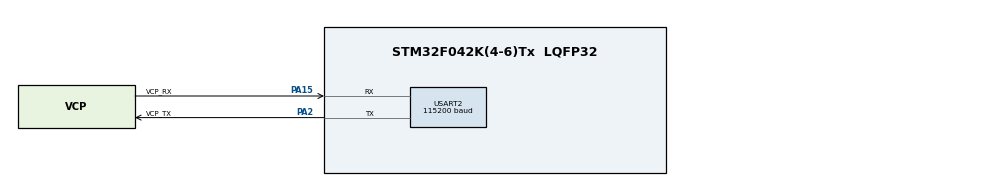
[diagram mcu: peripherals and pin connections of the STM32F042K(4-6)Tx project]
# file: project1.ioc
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Mcu.Family=STM32F0
Mcu.Name=STM32F042K(4-6)Tx
Mcu.Package=LQFP32
NVIC.USART2_IRQn=true\:0\:0\:false\:false\:true\:true\:true
PA13.GPIO_Label=SWDIO
PA13.Mode=Serial_Wire
PA13.Signal=SYS_SWDIO
PA14.GPIO_Label=SWCLK
PA14.Mode=Serial_Wire
PA14.Signal=SYS_SWCLK
PA15.GPIO_Label=VCP_RX
PA15.Mode=Asynchronous
PA15.Signal=USART2_RX
PA2.GPIO_Label=VCP_TX
PA2.Mode=Asynchronous
PA2.Signal=USART2_TX
PF0-OSC_IN.GPIO_Label=MCO
PF0-OSC_IN.Mode=HSE-External-Clock-Source
PF0-OSC_IN.Signal=RCC_OSC_IN
ProjectManager.HeapSize=0x200
ProjectManager.StackSize=0x400
ProjectManager.TargetToolchain=STM32CubeIDE
USART2.BaudRate=115200
USART2.VirtualMode-Asynchronous=VM_ASYNC
board=NUCLEO-F042K6

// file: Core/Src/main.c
/* USER CODE BEGIN Header */
/**
  ******************************************************************************
  * @file           : main.c
  * @brief          : Main program body
  ******************************************************************************
  * @attention
  *
  * Copyright (c) 2022 STMicroelectronics.
  * All rights reserved.
  *
  * This software is licensed under terms that can be found in the LICENSE file
  * in the root directory of this software component.
  * If no LICENSE file comes with this software, it is provided AS-IS.
  *
  ******************************************************************************
  */
/* USER CODE END Header */
#include "main.h"
#include "usart.h"
#include "gpio.h"
#include "jsmn.h"

/* USER CODE BEGIN PTD */
typedef unsigned char bool;

/* USER CODE END PTD */

/* USER CODE BEGIN PD */
#ifdef __GNUC__
  #define PUTCHAR_PROTOTYPE int __io_putchar(int ch)
#else
  #define PUTCHAR_PROTOTYPE int fputc(int ch, FILE *f)
#endif /* __GNUC__ */
#define BUFFER_SIZE 256
/* USER CODE END PD */

void SystemClock_Config(void);
/* USER CODE BEGIN PFP */
PUTCHAR_PROTOTYPE
{
	HAL_UART_Transmit(&huart2, (uint8_t *)&ch, 1, 0xFFFF);
	return ch;
}
/* USER CODE END PFP */

/* USER CODE BEGIN 0 */
uint8_t debug_rxBuf[BUFFER_SIZE];
uint8_t debug_rxData[BUFFER_SIZE];
uint8_t debug_aRxBuf;
uint8_t debug_rx_cnt = 0;
bool debug_rx_flag = false;
/* USER CODE END 0 */

int main(void)
{

  /* MCU Configuration--------------------------------------------------------*/

  /* Reset of all peripherals, Initializes the Flash interface and the Systick. */
  HAL_Init();

  /* Configure the system clock */
  SystemClock_Config();

  /* Initialize all configured peripherals */
  MX_GPIO_Init();
  MX_USART2_UART_Init();
  /* USER CODE BEGIN 2 */
  HAL_UART_Receive_IT(&huart2, &debug_aRxBuf, 1);

  /* USER CODE END 2 */

  /* Infinite loop */
  /* USER CODE BEGIN WHILE */
  printf("start\n");
  static const char *JSON_STRING =
      "{\"user\": \"johndoe\", \"admin\": false, \"uid\": 1000,\n  "
      "\"groups\": [\"users\", \"wheel\", \"audio\", \"video\"]}";
  jsmn_parser p;
  jsmntok_t t[128];
  jsmn_init(&p);
  int r = jsmn_parse(&p, JSON_STRING, strlen(JSON_STRING), t, sizeof(t)/sizeof(t[0]));
  for (int i = 1; i < r; i++)
  {
      if (jsoneq(JSON_STRING, &t[i], "user") == 0)
      {
          /* We may use strndup() to fetch string value */
          printf("- User: %.*s\n", t[i+1].end-t[i+1].start, JSON_STRING + t[i+1].start);
          i++;
      }
      else if (jsoneq(JSON_STRING, &t[i], "admin") == 0)
      {
           /* We may additionally check if the value is either "true" or "false" */
          printf("- Admin: %.*s\n", t[i+1].end-t[i+1].start, JSON_STRING + t[i+1].start);
          i++;
      }
  }
//  char text[]="{\"mode\":\"nest\",\"move\":0.7,\"turn\":-0.123,\"rc_servo\":{\"0\":125,\"3\":75,\"1\":0,\"11\":75},\"adc\":\"\",\"rc_request\":\"\"}";
//  cJSON *json,*result;
//  json = cJSON_Parse(text);
//  printf("json type = %d\n",json->type);
//  result  = cJSON_GetObjectItem(json,"mode");
//  printf("result type = %d\n",result->type);
//  printf("%s\n",result->valuestring);
//  result = cJSON_GetObjectItem(json,"rc_servo");
//  result = cJSON_GetObjectItem(result,"0");
//  printf("%d\n",result->valueint);
//  cJSON_Delete(json);
//  cJSON_Delete(result);

  while(1);
  while (1)
  {
	if (debug_rx_flag == true) {
		debug_rx_flag = false;
		char *msg = (char*)debug_rxData;
//		printf("recv: %s", msg);
		if (strcmp(msg, "adc")) {
			int adc = 87;
			printf("%d\n", adc);
		} else if (strcmp(msg, "adc")) {
			int adc = 87;
			printf("%d\n", adc);
		}
	}
    /* USER CODE END WHILE */

  }
}

void SystemClock_Config(void)
{
  RCC_OscInitTypeDef RCC_OscInitStruct = {0};
  RCC_ClkInitTypeDef RCC_ClkInitStruct = {0};

  /** Initializes the RCC Oscillators according to the specified parameters
  * in the RCC_OscInitTypeDef structure.
  */
  RCC_OscInitStruct.OscillatorType = RCC_OSCILLATORTYPE_HSI;
  RCC_OscInitStruct.HSIState = RCC_HSI_ON;
  RCC_OscInitStruct.HSICalibrationValue = RCC_HSICALIBRATION_DEFAULT;
  RCC_OscInitStruct.PLL.PLLState = RCC_PLL_NONE;
  if (HAL_RCC_OscConfig(&RCC_OscInitStruct) != HAL_OK)
  {
    Error_Handler();
  }
  /** Initializes the CPU, AHB and APB buses clocks
  */
  RCC_ClkInitStruct.ClockType = RCC_CLOCKTYPE_HCLK|RCC_CLOCKTYPE_SYSCLK
                              |RCC_CLOCKTYPE_PCLK1;
  RCC_ClkInitStruct.SYSCLKSource = RCC_SYSCLKSOURCE_HSI;
  RCC_ClkInitStruct.AHBCLKDivider = RCC_SYSCLK_DIV1;
  RCC_ClkInitStruct.APB1CLKDivider = RCC_HCLK_DIV1;

  if (HAL_RCC_ClockConfig(&RCC_ClkInitStruct, FLASH_LATENCY_0) != HAL_OK)
  {
    Error_Handler();
  }
}

/* USER CODE BEGIN 4 */

void HAL_UART_RxCpltCallback(UART_HandleTypeDef *huart) {
	debug_rxBuf[debug_rx_cnt++] = debug_aRxBuf;
	if (debug_aRxBuf == '\n') {
		debug_rx_flag = true;
		memcpy(debug_rxData, debug_rxBuf, BUFFER_SIZE);
		memset(debug_rxBuf, 0, BUFFER_SIZE);
		debug_rx_cnt = 0;
	}
	HAL_UART_Receive_IT(huart, &debug_aRxBuf, 1);
//	HAL_UART_Receive_DMA(huart, &debug_aRxBuf, 1);
}

/* USER CODE END 4 */

void Error_Handler(void)
{
  __disable_irq();
  while (1)
  {
  }
}
